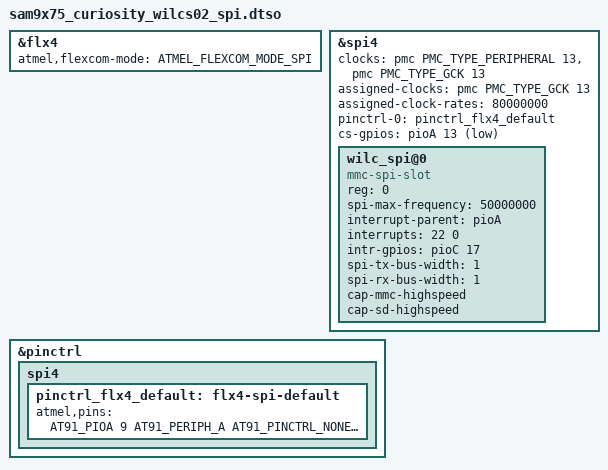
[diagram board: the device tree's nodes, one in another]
// SPDX-License-Identifier: (GPL-2.0+ OR MIT)
/*
 * Device Tree file for SAM9X75 CURIOSITY board
 * overlay blob for WILCS02 Wireless Module in SPI Mode
 * over M.2 connector
 *
 * Copyright (C) 2025 Microchip Technology, Inc.
 * Author: Manikandan Muralidharan <manikandan.m@microchip.com>
 *
 */
/dts-v1/;
/plugin/;

#include <dt-bindings/mfd/atmel-flexcom.h>
#include <dt-bindings/pinctrl/at91.h>
#include <dt-bindings/gpio/gpio.h>
#include <dt-bindings/clock/at91.h>

&flx4 {
	atmel,flexcom-mode = <ATMEL_FLEXCOM_MODE_SPI>;
	status = "okay";
};

&spi4 {
	#address-cells = <1>;
	#size-cells = <0>;
	clocks = <&pmc PMC_TYPE_PERIPHERAL 13>, <&pmc PMC_TYPE_GCK 13>;
	clock-names = "spi_clk", "spi_gclk";
	assigned-clocks = <&pmc PMC_TYPE_GCK 13>;
	assigned-clock-rates = <80000000>;
	pinctrl-names = "default";
	pinctrl-0 = <&pinctrl_flx4_default>;

	cs-gpios = <&pioA 13 GPIO_ACTIVE_LOW>;
	status = "okay";

	wilc_spi@0 {
		compatible = "mmc-spi-slot";
		reg = <0>;
		spi-max-frequency = <50000000>;
		interrupt-parent = <&pioA>;
		interrupts = <22 0>;
		intr-gpios = <&pioC 17 0>;
		spi-tx-bus-width = <1>;
		spi-rx-bus-width = <1>;
		cap-mmc-highspeed;
		cap-sd-highspeed;
		status = "okay";
	};
};

&pinctrl {
	spi4 {
		pinctrl_flx4_default: flx4-spi-default {
			atmel,pins =
				<AT91_PIOA 9 AT91_PERIPH_A AT91_PINCTRL_NONE		/* SPI MISO */
				 AT91_PIOA 10 AT91_PERIPH_A AT91_PINCTRL_NONE		/* SPI MOSI */
				 AT91_PIOA 11 AT91_PERIPH_A AT91_PINCTRL_NONE		/* SPI CLK  */
				 AT91_PIOA 13 AT91_PERIPH_B AT91_PINCTRL_NONE>;		/* SPI CS   */
		};
	};
};
